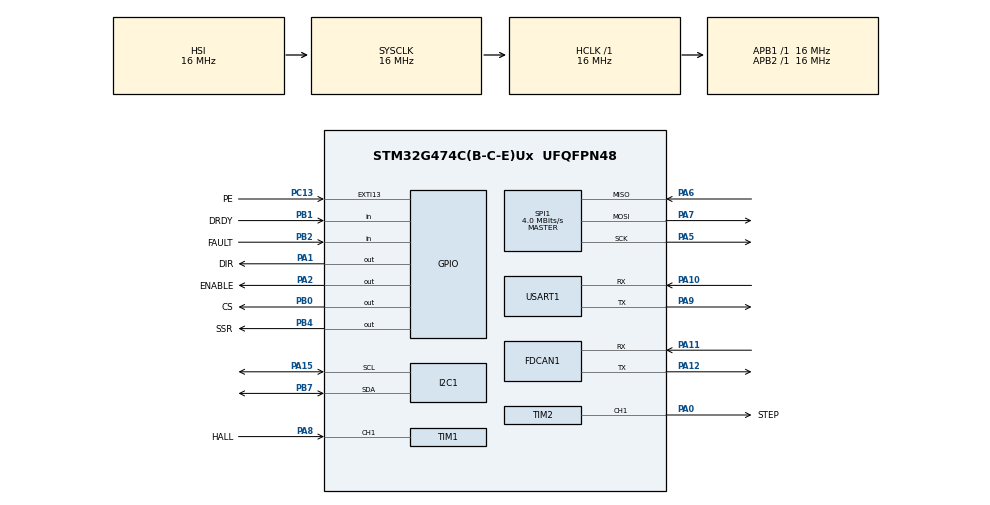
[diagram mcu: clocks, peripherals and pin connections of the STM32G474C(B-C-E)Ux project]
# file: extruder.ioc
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FDCAN1.AutoRetransmission=ENABLE
FDCAN1.CalculateBaudRateNominal=500000
FDCAN1.CalculateTimeBitNominal=2000
FDCAN1.CalculateTimeQuantumNominal=62.5
FDCAN1.DataTimeSeg1=1
FDCAN1.DataTimeSeg2=1
FDCAN1.NominalPrescaler=1
FDCAN1.NominalTimeSeg1=25
FDCAN1.NominalTimeSeg2=6
I2C1.Timing=0x00503D58
Mcu.Family=STM32G4
Mcu.Name=STM32G474C(B-C-E)Ux
Mcu.Package=UFQFPN48
NVIC.EXTI15_10_IRQn=true\:0\:0\:false\:false\:true\:true\:true\:true
NVIC.FDCAN1_IT0_IRQn=true\:0\:0\:false\:false\:true\:true\:true\:true
NVIC.PriorityGroup=NVIC_PRIORITYGROUP_4
NVIC.TIM1_CC_IRQn=true\:0\:0\:false\:false\:true\:true\:true\:true
PA0.GPIO_Label=STEP
PA0.Signal=S_TIM2_CH1
PA1.GPIO_Label=DIR
PA1.Signal=GPIO_Output
PA10.Mode=Asynchronous
PA10.Signal=USART1_RX
PA11.Mode=FDCAN_Activate
PA11.Signal=FDCAN1_RX
PA12.Mode=FDCAN_Activate
PA12.Signal=FDCAN1_TX
PA13.Mode=Serial_Wire
PA13.Signal=SYS_JTMS-SWDIO
PA14.Mode=Serial_Wire
PA14.Signal=SYS_JTCK-SWCLK
PA15.Mode=I2C
PA15.Signal=I2C1_SCL
PA2.GPIO_Label=ENABLE
PA2.Signal=GPIO_Output
PA5.Mode=Full_Duplex_Master
PA5.Signal=SPI1_SCK
PA6.Mode=Full_Duplex_Master
PA6.Signal=SPI1_MISO
PA7.Mode=Full_Duplex_Master
PA7.Signal=SPI1_MOSI
PA8.GPIO_Label=HALL
PA8.Signal=S_TIM1_CH1
PA9.Mode=Asynchronous
PA9.Signal=USART1_TX
PB0.GPIO_Label=CS
PB0.GPIO_PuPd=GPIO_NOPULL
PB0.PinState=GPIO_PIN_SET
PB0.Signal=GPIO_Output
PB1.GPIO_Label=DRDY
PB1.GPIO_PuPd=GPIO_PULLUP
PB1.Signal=GPIO_Input
PB2.GPIO_Label=FAULT
PB2.GPIO_PuPd=GPIO_PULLUP
PB2.Signal=GPIO_Input
PB4.GPIO_Label=SSR
PB4.Signal=GPIO_Output
PB7.Mode=I2C
PB7.Signal=I2C1_SDA
PC13.GPIO_Label=PE
PC13.GPIO_ModeDefaultEXTI=GPIO_MODE_IT_FALLING
PC13.GPIO_PuPd=GPIO_PULLUP
PC13.Signal=GPXTI13
ProjectManager.HeapSize=0x200
ProjectManager.StackSize=0x400
ProjectManager.TargetToolchain=STM32CubeIDE
RCC.AHBFreq_Value=16000000
RCC.APB1Freq_Value=16000000
RCC.APB1TimFreq_Value=16000000
RCC.APB2Freq_Value=16000000
RCC.APB2TimFreq_Value=16000000
RCC.CortexFreq_Value=16000000
RCC.EXTERNAL_CLOCK_VALUE=12288000
RCC.HCLKFreq_Value=16000000
RCC.HSE_VALUE=8000000
RCC.HSI48_VALUE=48000000
RCC.HSI_VALUE=16000000
RCC.LSE_VALUE=32768
RCC.SYSCLKFreq_VALUE=16000000
RCC.USBFreq_Value=64000000
RCC.VCOOutputFreq_Value=128000000
SH.S_TIM1_CH1.0=TIM1_CH1,Input_Capture1_from_TI1
SH.S_TIM2_CH1.0=TIM2_CH1,PWM Generation1 CH1
SPI1.BaudRatePrescaler=SPI_BAUDRATEPRESCALER_4
SPI1.CLKPhase=SPI_PHASE_2EDGE
SPI1.CalculateBaudRate=4.0 MBits/s
SPI1.DataSize=SPI_DATASIZE_8BIT
SPI1.Direction=SPI_DIRECTION_2LINES
SPI1.Mode=SPI_MODE_MASTER
SPI1.VirtualType=VM_MASTER
TIM1.Channel-Input_Capture1_from_TI1=TIM_CHANNEL_1
TIM1.Prescaler=15
TIM2.AutoReloadPreload=TIM_AUTORELOAD_PRELOAD_ENABLE
TIM2.Channel-PWM\ Generation1\ CH1=TIM_CHANNEL_1
TIM2.PeriodNoDither=999
TIM2.Prescaler=15
TIM2.PulseNoDither_1=500
USART1.VirtualMode-Asynchronous=VM_ASYNC
VP_SYS_VS_DBSignals.Mode=DisableDeadBatterySignals
VP_TIM1_VS_ClockSourceINT.Mode=Internal
VP_TIM2_VS_ClockSourceINT.Mode=Internal
board=custom

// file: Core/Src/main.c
/* USER CODE BEGIN Header */
/**
  ******************************************************************************
  * @file           : main.c
  * @brief          : Main program body
  ******************************************************************************
  * @attention
  *
  * Copyright (c) 2026 STMicroelectronics.
  * All rights reserved.
  *
  * This software is licensed under terms that can be found in the LICENSE file
  * in the root directory of this software component.
  * If no LICENSE file comes with this software, it is provided AS-IS.
  *
  ******************************************************************************
  */
/* USER CODE END Header */
#include "main.h"
#include "app.h"

FDCAN_HandleTypeDef hfdcan1;

I2C_HandleTypeDef hi2c1;

SPI_HandleTypeDef hspi1;

TIM_HandleTypeDef htim1;
TIM_HandleTypeDef htim2;

UART_HandleTypeDef huart1;

void SystemClock_Config(void);
static void MX_GPIO_Init(void);
static void MX_FDCAN1_Init(void);
static void MX_I2C1_Init(void);
static void MX_SPI1_Init(void);
static void MX_TIM1_Init(void);
static void MX_TIM2_Init(void);
static void MX_USART1_UART_Init(void);
/* USER CODE BEGIN PFP */
//void I2C_Scan(void);

/* USER CODE END PFP */

int main(void)
{

  /* MCU Configuration--------------------------------------------------------*/

  /* Reset of all peripherals, Initializes the Flash interface and the Systick. */
  HAL_Init();

  /* Configure the system clock */
  SystemClock_Config();

  /* Initialize all configured peripherals */
  MX_GPIO_Init();
  MX_FDCAN1_Init();
  MX_I2C1_Init();
  MX_SPI1_Init();
  MX_TIM1_Init();
  MX_TIM2_Init();
  MX_USART1_UART_Init();

  /* USER CODE BEGIN 2 */
  App_Init(1);
  /* USER CODE END 2 */

  /* Infinite loop */
  while (1)
  {
	  App_Loop();
  }
}

void SystemClock_Config(void)
{
  RCC_OscInitTypeDef RCC_OscInitStruct = {0};
  RCC_ClkInitTypeDef RCC_ClkInitStruct = {0};

  /** Configure the main internal regulator output voltage
  */
  HAL_PWREx_ControlVoltageScaling(PWR_REGULATOR_VOLTAGE_SCALE1);

  /** Initializes the RCC Oscillators according to the specified parameters
  * in the RCC_OscInitTypeDef structure.
  */
  RCC_OscInitStruct.OscillatorType = RCC_OSCILLATORTYPE_HSI;
  RCC_OscInitStruct.HSIState = RCC_HSI_ON;
  RCC_OscInitStruct.HSICalibrationValue = RCC_HSICALIBRATION_DEFAULT;
  RCC_OscInitStruct.PLL.PLLState = RCC_PLL_NONE;
  if (HAL_RCC_OscConfig(&RCC_OscInitStruct) != HAL_OK)
  {
    Error_Handler();
  }

  /** Initializes the CPU, AHB and APB buses clocks
  */
  RCC_ClkInitStruct.ClockType = RCC_CLOCKTYPE_HCLK|RCC_CLOCKTYPE_SYSCLK
                              |RCC_CLOCKTYPE_PCLK1|RCC_CLOCKTYPE_PCLK2;
  RCC_ClkInitStruct.SYSCLKSource = RCC_SYSCLKSOURCE_HSI;
  RCC_ClkInitStruct.AHBCLKDivider = RCC_SYSCLK_DIV1;
  RCC_ClkInitStruct.APB1CLKDivider = RCC_HCLK_DIV1;
  RCC_ClkInitStruct.APB2CLKDivider = RCC_HCLK_DIV1;

  if (HAL_RCC_ClockConfig(&RCC_ClkInitStruct, FLASH_LATENCY_0) != HAL_OK)
  {
    Error_Handler();
  }
}

static void MX_FDCAN1_Init(void)
{

  hfdcan1.Instance = FDCAN1;
  hfdcan1.Init.ClockDivider = FDCAN_CLOCK_DIV1;
  hfdcan1.Init.FrameFormat = FDCAN_FRAME_CLASSIC;
  hfdcan1.Init.Mode = FDCAN_MODE_NORMAL;
  hfdcan1.Init.AutoRetransmission = ENABLE;
  hfdcan1.Init.TransmitPause = DISABLE;
  hfdcan1.Init.ProtocolException = DISABLE;
  hfdcan1.Init.NominalPrescaler = 1;
  hfdcan1.Init.NominalSyncJumpWidth = 1;
  hfdcan1.Init.NominalTimeSeg1 = 25;
  hfdcan1.Init.NominalTimeSeg2 = 6;
  hfdcan1.Init.DataPrescaler = 1;
  hfdcan1.Init.DataSyncJumpWidth = 1;
  hfdcan1.Init.DataTimeSeg1 = 1;
  hfdcan1.Init.DataTimeSeg2 = 1;
  hfdcan1.Init.StdFiltersNbr = 0;
  hfdcan1.Init.ExtFiltersNbr = 0;
  hfdcan1.Init.TxFifoQueueMode = FDCAN_TX_FIFO_OPERATION;
  if (HAL_FDCAN_Init(&hfdcan1) != HAL_OK)
  {
    Error_Handler();
  }

}

static void MX_I2C1_Init(void)
{

  hi2c1.Instance = I2C1;
  hi2c1.Init.Timing = 0x00503D58;
  hi2c1.Init.OwnAddress1 = 0;
  hi2c1.Init.AddressingMode = I2C_ADDRESSINGMODE_7BIT;
  hi2c1.Init.DualAddressMode = I2C_DUALADDRESS_DISABLE;
  hi2c1.Init.OwnAddress2 = 0;
  hi2c1.Init.OwnAddress2Masks = I2C_OA2_NOMASK;
  hi2c1.Init.GeneralCallMode = I2C_GENERALCALL_DISABLE;
  hi2c1.Init.NoStretchMode = I2C_NOSTRETCH_DISABLE;
  if (HAL_I2C_Init(&hi2c1) != HAL_OK)
  {
    Error_Handler();
  }

  /** Configure Analogue filter
  */
  if (HAL_I2CEx_ConfigAnalogFilter(&hi2c1, I2C_ANALOGFILTER_ENABLE) != HAL_OK)
  {
    Error_Handler();
  }

  /** Configure Digital filter
  */
  if (HAL_I2CEx_ConfigDigitalFilter(&hi2c1, 0) != HAL_OK)
  {
    Error_Handler();
  }

}

static void MX_SPI1_Init(void)
{

  /* SPI1 parameter configuration*/
  hspi1.Instance = SPI1;
  hspi1.Init.Mode = SPI_MODE_MASTER;
  hspi1.Init.Direction = SPI_DIRECTION_2LINES;
  hspi1.Init.DataSize = SPI_DATASIZE_8BIT;
  hspi1.Init.CLKPolarity = SPI_POLARITY_LOW;
  hspi1.Init.CLKPhase = SPI_PHASE_2EDGE;
  hspi1.Init.NSS = SPI_NSS_SOFT;
  hspi1.Init.BaudRatePrescaler = SPI_BAUDRATEPRESCALER_4;
  hspi1.Init.FirstBit = SPI_FIRSTBIT_MSB;
  hspi1.Init.TIMode = SPI_TIMODE_DISABLE;
  hspi1.Init.CRCCalculation = SPI_CRCCALCULATION_DISABLE;
  hspi1.Init.CRCPolynomial = 7;
  hspi1.Init.CRCLength = SPI_CRC_LENGTH_DATASIZE;
  hspi1.Init.NSSPMode = SPI_NSS_PULSE_DISABLE;
  if (HAL_SPI_Init(&hspi1) != HAL_OK)
  {
    Error_Handler();
  }

}

static void MX_TIM1_Init(void)
{

  TIM_ClockConfigTypeDef sClockSourceConfig = {0};
  TIM_MasterConfigTypeDef sMasterConfig = {0};
  TIM_IC_InitTypeDef sConfigIC = {0};

  htim1.Instance = TIM1;
  htim1.Init.Prescaler = 15;
  htim1.Init.CounterMode = TIM_COUNTERMODE_UP;
  htim1.Init.Period = 65535;
  htim1.Init.ClockDivision = TIM_CLOCKDIVISION_DIV1;
  htim1.Init.RepetitionCounter = 0;
  htim1.Init.AutoReloadPreload = TIM_AUTORELOAD_PRELOAD_DISABLE;
  if (HAL_TIM_Base_Init(&htim1) != HAL_OK)
  {
    Error_Handler();
  }
  sClockSourceConfig.ClockSource = TIM_CLOCKSOURCE_INTERNAL;
  if (HAL_TIM_ConfigClockSource(&htim1, &sClockSourceConfig) != HAL_OK)
  {
    Error_Handler();
  }
  if (HAL_TIM_IC_Init(&htim1) != HAL_OK)
  {
    Error_Handler();
  }
  sMasterConfig.MasterOutputTrigger = TIM_TRGO_RESET;
  sMasterConfig.MasterOutputTrigger2 = TIM_TRGO2_RESET;
  sMasterConfig.MasterSlaveMode = TIM_MASTERSLAVEMODE_DISABLE;
  if (HAL_TIMEx_MasterConfigSynchronization(&htim1, &sMasterConfig) != HAL_OK)
  {
    Error_Handler();
  }
  sConfigIC.ICPolarity = TIM_INPUTCHANNELPOLARITY_RISING;
  sConfigIC.ICSelection = TIM_ICSELECTION_DIRECTTI;
  sConfigIC.ICPrescaler = TIM_ICPSC_DIV1;
  sConfigIC.ICFilter = 0;
  if (HAL_TIM_IC_ConfigChannel(&htim1, &sConfigIC, TIM_CHANNEL_1) != HAL_OK)
  {
    Error_Handler();
  }

}

static void MX_TIM2_Init(void)
{

  TIM_ClockConfigTypeDef sClockSourceConfig = {0};
  TIM_MasterConfigTypeDef sMasterConfig = {0};
  TIM_OC_InitTypeDef sConfigOC = {0};

  htim2.Instance = TIM2;
  htim2.Init.Prescaler = 15;
  htim2.Init.CounterMode = TIM_COUNTERMODE_UP;
  htim2.Init.Period = 999;
  htim2.Init.ClockDivision = TIM_CLOCKDIVISION_DIV1;
  htim2.Init.AutoReloadPreload = TIM_AUTORELOAD_PRELOAD_ENABLE;
  if (HAL_TIM_Base_Init(&htim2) != HAL_OK)
  {
    Error_Handler();
  }
  sClockSourceConfig.ClockSource = TIM_CLOCKSOURCE_INTERNAL;
  if (HAL_TIM_ConfigClockSource(&htim2, &sClockSourceConfig) != HAL_OK)
  {
    Error_Handler();
  }
  if (HAL_TIM_PWM_Init(&htim2) != HAL_OK)
  {
    Error_Handler();
  }
  sMasterConfig.MasterOutputTrigger = TIM_TRGO_RESET;
  sMasterConfig.MasterSlaveMode = TIM_MASTERSLAVEMODE_DISABLE;
  if (HAL_TIMEx_MasterConfigSynchronization(&htim2, &sMasterConfig) != HAL_OK)
  {
    Error_Handler();
  }
  sConfigOC.OCMode = TIM_OCMODE_PWM1;
  sConfigOC.Pulse = 500;
  sConfigOC.OCPolarity = TIM_OCPOLARITY_HIGH;
  sConfigOC.OCFastMode = TIM_OCFAST_DISABLE;
  if (HAL_TIM_PWM_ConfigChannel(&htim2, &sConfigOC, TIM_CHANNEL_1) != HAL_OK)
  {
    Error_Handler();
  }
  HAL_TIM_MspPostInit(&htim2);

}

static void MX_USART1_UART_Init(void)
{

  huart1.Instance = USART1;
  huart1.Init.BaudRate = 115200;
  huart1.Init.WordLength = UART_WORDLENGTH_8B;
  huart1.Init.StopBits = UART_STOPBITS_1;
  huart1.Init.Parity = UART_PARITY_NONE;
  huart1.Init.Mode = UART_MODE_TX_RX;
  huart1.Init.HwFlowCtl = UART_HWCONTROL_NONE;
  huart1.Init.OverSampling = UART_OVERSAMPLING_16;
  huart1.Init.OneBitSampling = UART_ONE_BIT_SAMPLE_DISABLE;
  huart1.Init.ClockPrescaler = UART_PRESCALER_DIV1;
  huart1.AdvancedInit.AdvFeatureInit = UART_ADVFEATURE_NO_INIT;
  if (HAL_UART_Init(&huart1) != HAL_OK)
  {
    Error_Handler();
  }
  if (HAL_UARTEx_SetTxFifoThreshold(&huart1, UART_TXFIFO_THRESHOLD_1_8) != HAL_OK)
  {
    Error_Handler();
  }
  if (HAL_UARTEx_SetRxFifoThreshold(&huart1, UART_RXFIFO_THRESHOLD_1_8) != HAL_OK)
  {
    Error_Handler();
  }
  if (HAL_UARTEx_DisableFifoMode(&huart1) != HAL_OK)
  {
    Error_Handler();
  }

}

static void MX_GPIO_Init(void)
{
  GPIO_InitTypeDef GPIO_InitStruct = {0};

  /* GPIO Ports Clock Enable */
  __HAL_RCC_GPIOC_CLK_ENABLE();
  __HAL_RCC_GPIOA_CLK_ENABLE();
  __HAL_RCC_GPIOB_CLK_ENABLE();

  /*Configure GPIO pin Output Level */
  HAL_GPIO_WritePin(GPIOA, DIR_Pin|ENABLE_Pin, GPIO_PIN_RESET);

  /*Configure GPIO pin Output Level */
  HAL_GPIO_WritePin(CS_GPIO_Port, CS_Pin, GPIO_PIN_SET);

  /*Configure GPIO pin Output Level */
  HAL_GPIO_WritePin(SSR_GPIO_Port, SSR_Pin, GPIO_PIN_RESET);

  /*Configure GPIO pin : PE_Pin */
  GPIO_InitStruct.Pin = PE_Pin;
  GPIO_InitStruct.Mode = GPIO_MODE_IT_FALLING;
  GPIO_InitStruct.Pull = GPIO_PULLUP;
  HAL_GPIO_Init(PE_GPIO_Port, &GPIO_InitStruct);

  /*Configure GPIO pins : DIR_Pin ENABLE_Pin */
  GPIO_InitStruct.Pin = DIR_Pin|ENABLE_Pin;
  GPIO_InitStruct.Mode = GPIO_MODE_OUTPUT_PP;
  GPIO_InitStruct.Pull = GPIO_NOPULL;
  GPIO_InitStruct.Speed = GPIO_SPEED_FREQ_LOW;
  HAL_GPIO_Init(GPIOA, &GPIO_InitStruct);

  /*Configure GPIO pins : CS_Pin SSR_Pin */
  GPIO_InitStruct.Pin = CS_Pin|SSR_Pin;
  GPIO_InitStruct.Mode = GPIO_MODE_OUTPUT_PP;
  GPIO_InitStruct.Pull = GPIO_NOPULL;
  GPIO_InitStruct.Speed = GPIO_SPEED_FREQ_LOW;
  HAL_GPIO_Init(GPIOB, &GPIO_InitStruct);

  /*Configure GPIO pins : DRDY_Pin FAULT_Pin */
  GPIO_InitStruct.Pin = DRDY_Pin|FAULT_Pin;
  GPIO_InitStruct.Mode = GPIO_MODE_INPUT;
  GPIO_InitStruct.Pull = GPIO_PULLUP;
  HAL_GPIO_Init(GPIOB, &GPIO_InitStruct);

  /* EXTI interrupt init*/
  HAL_NVIC_SetPriority(EXTI15_10_IRQn, 0, 0);
  HAL_NVIC_EnableIRQ(EXTI15_10_IRQn);

}

void Error_Handler(void)
{
  __disable_irq();
  while (1)
  {
  }
}
